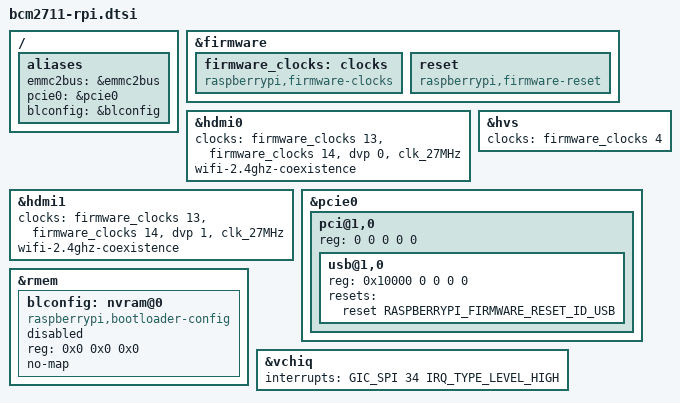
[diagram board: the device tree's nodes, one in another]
// SPDX-License-Identifier: GPL-2.0
#include "bcm2835-rpi.dtsi"

#include <dt-bindings/reset/raspberrypi,firmware-reset.h>

/ {
	aliases {
		emmc2bus = &emmc2bus;
		pcie0 = &pcie0;
		blconfig = &blconfig;
	};
};

&firmware {
	firmware_clocks: clocks {
		compatible = "raspberrypi,firmware-clocks";
		#clock-cells = <1>;
	};

	reset: reset {
		compatible = "raspberrypi,firmware-reset";
		#reset-cells = <1>;
	};
};

&hdmi0 {
	clocks = <&firmware_clocks 13>, <&firmware_clocks 14>, <&dvp 0>, <&clk_27MHz>;
	clock-names = "hdmi", "bvb", "audio", "cec";
	wifi-2.4ghz-coexistence;
};

&hdmi1 {
	clocks = <&firmware_clocks 13>, <&firmware_clocks 14>, <&dvp 1>, <&clk_27MHz>;
	clock-names = "hdmi", "bvb", "audio", "cec";
	wifi-2.4ghz-coexistence;
};

&hvs {
	clocks = <&firmware_clocks 4>;
};

&pcie0 {
	pci@1,0 {
		#address-cells = <3>;
		#size-cells = <2>;
		ranges;

		reg = <0 0 0 0 0>;

		usb@1,0 {
			reg = <0x10000 0 0 0 0>;
			resets = <&reset RASPBERRYPI_FIRMWARE_RESET_ID_USB>;
		};
	};
};

&rmem {
	/*
	 * RPi4's co-processor will copy the board's bootloader configuration
	 * into memory for the OS to consume. It'll also update this node with
	 * its placement information.
	 */
	blconfig: nvram@0 {
		compatible = "raspberrypi,bootloader-config", "nvmem-rmem";
		#address-cells = <1>;
		#size-cells = <1>;
		reg = <0x0 0x0 0x0>;
		no-map;
		status = "disabled";
	};
};

&vchiq {
	interrupts = <GIC_SPI 34 IRQ_TYPE_LEVEL_HIGH>;
};
